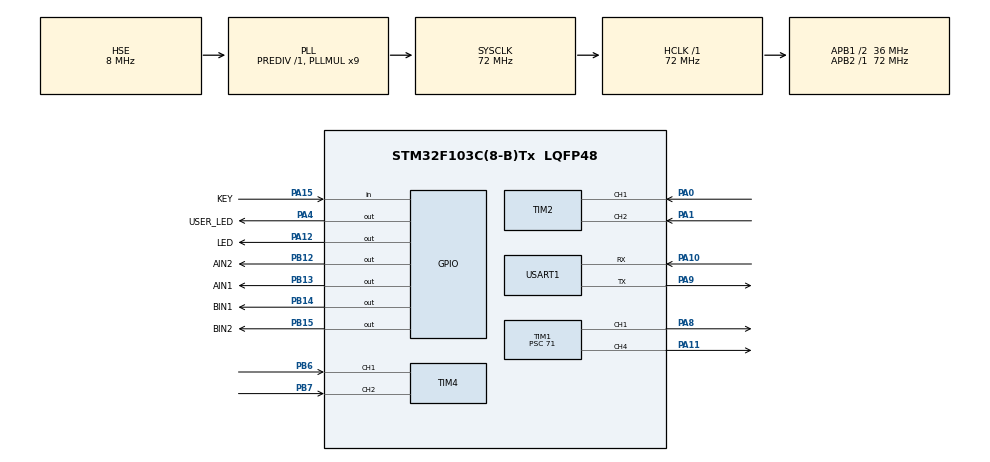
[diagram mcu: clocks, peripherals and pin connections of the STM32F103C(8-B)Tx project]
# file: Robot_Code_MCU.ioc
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FREERTOS.Tasks01=defaultTask,0,128,StartDefaultTask,Default,NULL,Dynamic,NULL,NULL;UserTask,-2,128,User_Task,As external,NULL,Dynamic,NULL,NULL;ContralTask,0,128,Contral_Task,As external,NULL,Dynamic,NULL,NULL
Mcu.Family=STM32F1
Mcu.Name=STM32F103C(8-B)Tx
Mcu.Package=LQFP48
NVIC.PriorityGroup=NVIC_PRIORITYGROUP_4
PA0-WKUP.Signal=S_TIM2_CH1_ETR
PA1.Signal=S_TIM2_CH2
PA10.Mode=Asynchronous
PA10.Signal=USART1_RX
PA11.Signal=S_TIM1_CH4
PA12.GPIO_Label=LED
PA12.Signal=GPIO_Output
PA13.Mode=Serial_Wire
PA13.Signal=SYS_JTMS-SWDIO
PA14.Mode=Serial_Wire
PA14.Signal=SYS_JTCK-SWCLK
PA15.GPIO_Label=KEY
PA15.Signal=GPIO_Input
PA4.GPIO_Label=USER_LED
PA4.Signal=GPIO_Output
PA8.Signal=S_TIM1_CH1
PA9.Mode=Asynchronous
PA9.Signal=USART1_TX
PB12.GPIO_Label=AIN2
PB12.Signal=GPIO_Output
PB13.GPIO_Label=AIN1
PB13.Signal=GPIO_Output
PB14.GPIO_Label=BIN1
PB14.Signal=GPIO_Output
PB15.GPIO_Label=BIN2
PB15.Signal=GPIO_Output
PB6.Signal=S_TIM4_CH1
PB7.Signal=S_TIM4_CH2
PD0-OSC_IN.Mode=HSE-External-Oscillator
PD0-OSC_IN.Signal=RCC_OSC_IN
PD1-OSC_OUT.Mode=HSE-External-Oscillator
PD1-OSC_OUT.Signal=RCC_OSC_OUT
ProjectManager.HeapSize=0x200
ProjectManager.StackSize=0x400
ProjectManager.TargetToolchain=MDK-ARM V5.27
RCC.AHBFreq_Value=72000000
RCC.APB1CLKDivider=RCC_HCLK_DIV2
RCC.APB1Freq_Value=36000000
RCC.APB1TimFreq_Value=72000000
RCC.APB2Freq_Value=72000000
RCC.APB2TimFreq_Value=72000000
RCC.HCLKFreq_Value=72000000
RCC.PLLMUL=RCC_PLL_MUL9
RCC.PLLSourceVirtual=RCC_PLLSOURCE_HSE
RCC.SYSCLKFreq_VALUE=72000000
RCC.SYSCLKSource=RCC_SYSCLKSOURCE_PLLCLK
RCC.USBFreq_Value=72000000
SH.S_TIM1_CH1.0=TIM1_CH1,PWM Generation1 CH1
SH.S_TIM1_CH4.0=TIM1_CH4,PWM Generation4 CH4
SH.S_TIM2_CH1_ETR.0=TIM2_CH1
SH.S_TIM2_CH1_ETR.1=TIM2_CH1,Input_Capture1_from_TI1
SH.S_TIM2_CH2.0=TIM2_CH2
SH.S_TIM2_CH2.1=TIM2_CH2,Input_Capture2_from_TI2
SH.S_TIM4_CH1.0=TIM4_CH1,Input_Capture1_from_TI1
SH.S_TIM4_CH2.0=TIM4_CH2,Input_Capture2_from_TI2
TIM1.AutoReloadPreload=TIM_AUTORELOAD_PRELOAD_ENABLE
TIM1.Channel-PWM\ Generation1\ CH1=TIM_CHANNEL_1
TIM1.Channel-PWM\ Generation4\ CH4=TIM_CHANNEL_4
TIM1.Period=99
TIM1.Prescaler=71
TIM2.Channel-Input_Capture1_from_TI1=TIM_CHANNEL_1
TIM2.Channel-Input_Capture2_from_TI2=TIM_CHANNEL_2
TIM2.ICPolarity_CH2=TIM_INPUTCHANNELPOLARITY_FALLING
TIM4.Channel-Input_Capture1_from_TI1=TIM_CHANNEL_1
TIM4.Channel-Input_Capture2_from_TI2=TIM_CHANNEL_2
TIM4.ICPolarity_CH2=TIM_INPUTCHANNELPOLARITY_FALLING
USART1.VirtualMode=VM_ASYNC
VP_FREERTOS_VS_CMSIS_V1.Mode=CMSIS_V1
VP_TIM1_VS_ClockSourceINT.Mode=Internal
board=custom

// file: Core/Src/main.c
/* USER CODE BEGIN Header */
/**
  ******************************************************************************
  * @file           : main.c
  * @brief          : Main program body
  ******************************************************************************
  * @attention
  *
  * <h2><center>&copy; Copyright (c) 2021 STMicroelectronics.
  * All rights reserved.</center></h2>
  *
  * This software component is licensed by ST under BSD 3-Clause license,
  * the "License"; You may not use this file except in compliance with the
  * License. You may obtain a copy of the License at:
  *                        opensource.org/licenses/BSD-3-Clause
  *
  ******************************************************************************
  */
/* USER CODE END Header */
#include "main.h"
#include "cmsis_os.h"
#include "tim.h"
#include "usart.h"
#include "gpio.h"

void SystemClock_Config(void);
void MX_FREERTOS_Init(void);

int main(void)
{

  /* MCU Configuration--------------------------------------------------------*/

  /* Reset of all peripherals, Initializes the Flash interface and the Systick. */
  HAL_Init();

  /* Configure the system clock */
  SystemClock_Config();

  /* Initialize all configured peripherals */
  MX_GPIO_Init();
  MX_USART1_UART_Init();
  MX_TIM1_Init();
  MX_TIM2_Init();
  MX_TIM4_Init();
  /* USER CODE BEGIN 2 */
	HAL_TIM_PWM_Start(&htim1,TIM_CHANNEL_1);
	HAL_TIM_PWM_Start(&htim1,TIM_CHANNEL_4);
  /* USER CODE END 2 */

  /* Call init function for freertos objects (in freertos.c) */
  MX_FREERTOS_Init();
  /* Start scheduler */
  osKernelStart();

  /* We should never get here as control is now taken by the scheduler */
  /* Infinite loop */
  while (1)
  {

  }
}

void SystemClock_Config(void)
{
  RCC_OscInitTypeDef RCC_OscInitStruct = {0};
  RCC_ClkInitTypeDef RCC_ClkInitStruct = {0};

  /** Initializes the RCC Oscillators according to the specified parameters
  * in the RCC_OscInitTypeDef structure.
  */
  RCC_OscInitStruct.OscillatorType = RCC_OSCILLATORTYPE_HSE;
  RCC_OscInitStruct.HSEState = RCC_HSE_ON;
  RCC_OscInitStruct.HSEPredivValue = RCC_HSE_PREDIV_DIV1;
  RCC_OscInitStruct.HSIState = RCC_HSI_ON;
  RCC_OscInitStruct.PLL.PLLState = RCC_PLL_ON;
  RCC_OscInitStruct.PLL.PLLSource = RCC_PLLSOURCE_HSE;
  RCC_OscInitStruct.PLL.PLLMUL = RCC_PLL_MUL9;
  if (HAL_RCC_OscConfig(&RCC_OscInitStruct) != HAL_OK)
  {
    Error_Handler();
  }
  /** Initializes the CPU, AHB and APB buses clocks
  */
  RCC_ClkInitStruct.ClockType = RCC_CLOCKTYPE_HCLK|RCC_CLOCKTYPE_SYSCLK
                              |RCC_CLOCKTYPE_PCLK1|RCC_CLOCKTYPE_PCLK2;
  RCC_ClkInitStruct.SYSCLKSource = RCC_SYSCLKSOURCE_PLLCLK;
  RCC_ClkInitStruct.AHBCLKDivider = RCC_SYSCLK_DIV1;
  RCC_ClkInitStruct.APB1CLKDivider = RCC_HCLK_DIV2;
  RCC_ClkInitStruct.APB2CLKDivider = RCC_HCLK_DIV1;

  if (HAL_RCC_ClockConfig(&RCC_ClkInitStruct, FLASH_LATENCY_2) != HAL_OK)
  {
    Error_Handler();
  }
}

void Error_Handler(void)
{
}

/************************ (C) COPYRIGHT STMicroelectronics *****END OF FILE****/

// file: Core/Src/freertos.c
/* USER CODE BEGIN Header */
/**
  ******************************************************************************
  * File Name          : freertos.c
  * Description        : Code for freertos applications
  ******************************************************************************
  * @attention
  *
  * <h2><center>&copy; Copyright (c) 2021 STMicroelectronics.
  * All rights reserved.</center></h2>
  *
  * This software component is licensed by ST under Ultimate Liberty license
  * SLA0044, the "License"; You may not use this file except in compliance with
  * the License. You may obtain a copy of the License at:
  *                             www.st.com/SLA0044
  *
  ******************************************************************************
  */
/* USER CODE END Header */

#include "FreeRTOS.h"
#include "task.h"
#include "main.h"
#include "cmsis_os.h"

/* USER CODE BEGIN Includes */
#include "user_task.h"

/* USER CODE END Includes */

osThreadId defaultTaskHandle;
osThreadId UserTaskHandle;
osThreadId ContralTaskHandle;

void StartDefaultTask(void const * argument);
extern void User_Task(void const * argument);
extern void Contral_Task(void const * argument);

void MX_FREERTOS_Init(void); /* (MISRA C 2004 rule 8.1) */

/* GetIdleTaskMemory prototype (linked to static allocation support) */
void vApplicationGetIdleTaskMemory( StaticTask_t **ppxIdleTaskTCBBuffer, StackType_t **ppxIdleTaskStackBuffer, uint32_t *pulIdleTaskStackSize );

/* USER CODE BEGIN GET_IDLE_TASK_MEMORY */
static StaticTask_t xIdleTaskTCBBuffer;
static StackType_t xIdleStack[configMINIMAL_STACK_SIZE];

void vApplicationGetIdleTaskMemory( StaticTask_t **ppxIdleTaskTCBBuffer, StackType_t **ppxIdleTaskStackBuffer, uint32_t *pulIdleTaskStackSize )
{
  *ppxIdleTaskTCBBuffer = &xIdleTaskTCBBuffer;
  *ppxIdleTaskStackBuffer = &xIdleStack[0];
  *pulIdleTaskStackSize = configMINIMAL_STACK_SIZE;
  /* place for user code */
}
/* USER CODE END GET_IDLE_TASK_MEMORY */

void MX_FREERTOS_Init(void) {

  /* Create the thread(s) */
  /* definition and creation of defaultTask */
  osThreadDef(defaultTask, StartDefaultTask, osPriorityNormal, 0, 128);
  defaultTaskHandle = osThreadCreate(osThread(defaultTask), NULL);

  /* definition and creation of UserTask */
  osThreadDef(UserTask, User_Task, osPriorityLow, 0, 128);
  UserTaskHandle = osThreadCreate(osThread(UserTask), NULL);

  /* definition and creation of ContralTask */
  osThreadDef(ContralTask, Contral_Task, osPriorityNormal, 0, 128);
  ContralTaskHandle = osThreadCreate(osThread(ContralTask), NULL);

}

void StartDefaultTask(void const * argument)
{
  for(;;)
  {
    osDelay(1);
  }
}

/************************ (C) COPYRIGHT STMicroelectronics *****END OF FILE****/
